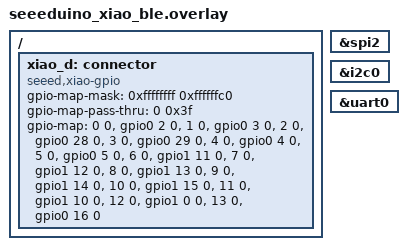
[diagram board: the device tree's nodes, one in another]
/*
 * Copyright (c) 2022 Peter Johanson
 *
 * SPDX-License-Identifier: Apache-2.0
 */

/ {
	xiao_d: connector {
		compatible = "seeed,xiao-gpio";
		#gpio-cells = <2>;
		gpio-map-mask = <0xffffffff 0xffffffc0>;
		gpio-map-pass-thru = <0 0x3f>;
		gpio-map
			= <0 0 &gpio0 2 0>		/* D0/A0 for strain gauge x */
			, <1 0 &gpio0 3 0>		/* D1/A1 for strain gauge y*/
			, <2 0 &gpio0 28 0>		/* D2/A2 for strain gauge power*/
			, <3 0 &gpio0 29 0>		/* D3/A3 C2 */
			, <4 0 &gpio0 4 0>		/* D4/A4 C3 */
			, <5 0 &gpio0 5 0>		/* D5/A5 C4 */
			, <6 0 &gpio1 11 0>		/* D6    C5 */
			, <7 0 &gpio1 12 0>		/* D7    R3 */
			, <8 0 &gpio1 13 0>		/* D8    R2 */
			, <9 0 &gpio1 14 0>		/* D9    R1 */
			, <10 0 &gpio1 15 0>		/* D10   R0 */
			, <11 0 &gpio1 10 0>		/* D11      for MIC power with C */
			, <12 0 &gpio1 0 0>		/* D12   C0 for MIC CLK */
			, <13 0 &gpio0 16 0>		/* D13   C1 for MIC DATA */
			;
	};
};

xiao_spi: &spi2 {};
xiao_i2c: &i2c0 {};
xiao_serial: &uart0 {};
